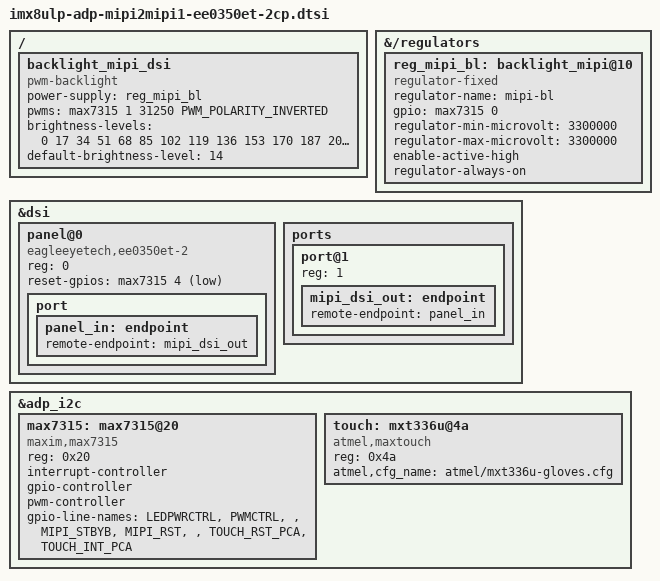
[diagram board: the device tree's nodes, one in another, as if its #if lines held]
// SPDX-License-Identifier: GPL-2.0
/*
* Copyright 2024 F&S Elektronik Systeme GmbH
*
* This program is free software; you can redistribute it and/or modify
* it under the terms of the GNU General Public License version 2 as
* published by the Free Software Foundation.
*
* This program is distributed in the hope that it will be useful,
* but WITHOUT ANY WARRANTY; without even the implied warranty of
* MERCHANTABILITY or FITNESS FOR A PARTICULAR PURPOSE.  See the
* GNU General Public License for more details.
*/

#if CONFIG_ADP_MIPI2MIPI1_BOARD_REVISION != 120 && \
    CONFIG_ADP_MIPI2MIPI1_BOARD_REVISION != 100
#error "no revision defined or unsupported"
#endif

#include <dt-bindings/pwm/pwm.h>

/ {
    /* MIPI-DSI backlight PWM on adapter MIPI2MIPI1 */
    backlight_mipi_dsi {
        compatible = "pwm-backlight";
        power-supply = <&reg_mipi_bl>;

#if CONFIG_ADP_MIPI2MIPI1_BOARD_REVISION == 120
        /* only 32 kHz available */
        pwms = <&max7315 1 31250 PWM_POLARITY_INVERTED>;
        /* calculated without sigma so it´s linear */
        brightness-levels = <0 17 34 51 68 85 102 119 136
                                153 170 187 204 221 238 255>;
#elif CONFIG_ADP_MIPI2MIPI1_BOARD_REVISION == 100
        pwms = <&pca963x 0 640000 0>; /* 1.5625 kHz */
        brightness-levels = <0 30 32 35 39 46 55 66
                                80 96 115 137 162 190 221 255>;
#endif
        default-brightness-level = <14>;
	};
};


&{/regulators} {
	reg_mipi_bl: backlight_mipi@10 {
        compatible = "regulator-fixed";
        regulator-name = "mipi-bl";
#if CONFIG_ADP_MIPI2MIPI1_BOARD_REVISION == 120
        gpio = <&max7315 0 GPIO_ACTIVE_HIGH>;
#elif CONFIG_ADP_MIPI2MIPI1_BOARD_REVISION == 100
        gpio = <&pca963x 1 GPIO_ACTIVE_HIGH>;
#endif
        regulator-min-microvolt = <3300000>;
        regulator-max-microvolt = <3300000>;
        enable-active-high;
		regulator-always-on;
	};
};

&dsi {
	#address-cells = <1>;
	#size-cells = <0>;
	status = "okay";
	
	panel@0 {
        compatible = "eagleeyetech,ee0350et-2";
        reg = <0>;
#if CONFIG_ADP_MIPI2MIPI1_BOARD_REVISION == 120
		reset-gpios = <&max7315 4 GPIO_ACTIVE_LOW>;
#elif CONFIG_ADP_MIPI2MIPI1_BOARD_REVISION == 100
		reset-gpios = <&pca963x 2 GPIO_ACTIVE_HIGH>;
#endif

		port {
			panel_in: endpoint {
				remote-endpoint = <&mipi_dsi_out>;
			};
		};
	};

	ports {
		port@1 {
			reg = <1>;

			mipi_dsi_out: endpoint {
				remote-endpoint = <&panel_in>;
			};
		};
	};
};

&adp_i2c {
#if CONFIG_ADP_MIPI2MIPI1_BOARD_REVISION == 120
	/* LED-driver on adapter board MIPI2MIPI1 */
	max7315: max7315@20 { /* LED-driver */
		compatible = "maxim,max7315";
		reg = <0x20>;
		#interrupt-cells = <2>;
		interrupt-controller;
		gpio-controller;
		#gpio-cells = <2>;
		pwm-controller;
		#pwm-cells = <3>;
		gpio-line-names = 
			"LEDPWRCTRL",
			"PWMCTRL",
			"",
			"MIPI_STBYB",
			"MIPI_RST",
			"",
			"TOUCH_RST_PCA",
			"TOUCH_INT_PCA";
	};
#elif CONFIG_ADP_MIPI2MIPI1_BOARD_REVISION == 100
	/* LED-driver on adapter board MIPI2MIPI1 */
	pca963x: pca9632@60 { /* LED-driver */
		compatible = "nxp,pca9632";
		reg = <0x60>;
		nxp,totem-pole;
		#address-cells = <1>;
		#size-cells = <0>;
		#pwm-cells = <3>;
		#gpio-cells = <2>;
		led@0 {
			reg = <0>;
			label = "1-LEDCTRL";
			type = "PWM";
			default-on;		/* or: keep-value */
			active-low;
		};
		led@1 {
			reg = <1>;
			label = "0-PWRCTL";
			type = "GPIO";
			default-on;		/* or: keep-value */
			active-high;
		};
		led@2 {
			reg = <2>;
			label = "2-TOUCH-RST";
			type = "GPIO";
			active-low;
		};
		led@3 {
			reg = <3>;
			label = "2-MIPI-RST";
			type = "GPIO";
			active-low;
		};
	};
#endif
	/* Atmel PCAP touch on Touch Connector (I2C) */
	touch: mxt336u@4a {
		compatible = "atmel,maxtouch";
		reg = <0x4a>;
		atmel,cfg_name = "atmel/mxt336u-gloves.cfg";
	};
};
